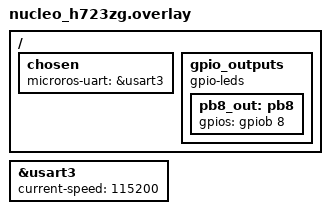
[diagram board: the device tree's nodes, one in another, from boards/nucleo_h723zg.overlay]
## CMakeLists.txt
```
# SPDX-License-Identifier: Apache-2.0
cmake_minimum_required(VERSION 3.14)

find_package(Zephyr REQUIRED HINTS $ENV{ZEPHYR_BASE})
project(wamr_led_toggle)
enable_language(ASM)

set(WAMR_BUILD_PLATFORM "zephyr")
set(WAMR_BUILD_INTERP 1)
set(WAMR_BUILD_LIBC_BUILTIN 1)
set(WAMR_BUILD_LIBC_WASI 0)
set(WAMR_BUILD_FAST_INTERP 0)
set(WAMR_BUILD_GLOBAL_HEAP_POOL 1)
set(WAMR_BUILD_GLOBAL_HEAP_SIZE 131072)

set(WAMR_ROOT_DIR $ENV{WAMR_ROOT} CACHE PATH "Path to WAMR root directory")

include(${WAMR_ROOT_DIR}/build-scripts/runtime_lib.cmake)

target_sources(app PRIVATE
    ${WAMR_RUNTIME_LIB_SOURCE}
    ${CMAKE_CURRENT_SOURCE_DIR}/src/main.c
    ${CMAKE_CURRENT_SOURCE_DIR}/src/wasm_export_native.c
)

target_include_directories(app PRIVATE
    ${APP_INC_DIRS}
    ${CMAKE_CURRENT_SOURCE_DIR}/include
)
```

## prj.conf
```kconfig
# Configurazione Memoria
CONFIG_NEWLIB_LIBC=y
CONFIG_COMMON_LIBC_MALLOC_ARENA_SIZE=0
CONFIG_HEAP_MEM_POOL_SIZE=2048

# Stack per l'interprete WAMR (fondamentale per evitare Hard Fault)
CONFIG_MAIN_STACK_SIZE=8192
CONFIG_SYSTEM_WORKQUEUE_STACK_SIZE=4096

# Periferiche e Log
CONFIG_GPIO=y
CONFIG_LOG=y
CONFIG_LOG_DEFAULT_LEVEL=3
CONFIG_UART_CONSOLE=y
CONFIG_CONSOLE=y

# Supporto Floating Point (Essenziale per FFT)
CONFIG_FPU=y

CONFIG_CACHE_MANAGEMENT=y
```

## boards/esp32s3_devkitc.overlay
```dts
/ {
    aliases {
        led0 = &d13_led;
    };
    leds {
        compatible = "gpio-leds";
        d13_led: d13 {
            gpios = <&gpio0 13 GPIO_ACTIVE_HIGH>;
        };
    };
};
```

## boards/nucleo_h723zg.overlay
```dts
/*
 * nucleo_h723zg.overlay
 *
 * NUCLEO-H723ZG: USART3 è collegato alla ST-Link (Virtual COM Port)
 * su PD8 (TX) / PD9 (RX).
 */
/ {
    chosen {
        microros-uart = &usart3;
    };
    gpio_outputs {
        compatible = "gpio-leds";
        pb8_out: pb8 {
            gpios = <&gpiob 8 GPIO_ACTIVE_HIGH>;
        };
    };
};

&usart3 {
    status = "okay";
    current-speed = <115200>;
};
```

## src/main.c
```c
#include <zephyr/kernel.h>
#include <zephyr/device.h>
#include <zephyr/drivers/gpio.h>
#include <zephyr/logging/log.h>
#include "wasm_export.h"
#include "wasm_native.h"
#include "wamr_benchmark.h"

LOG_MODULE_REGISTER(main, LOG_LEVEL_INF);

/* ── WAMR sizing ─────────────────────────────────────────────────────────── */
#define WASM_STACK_SIZE   8192
#define WASM_HEAP_SIZE    8192




/* ── main ─────────────────────────────────────────────────────────────────── */
int main(void)
{
    printk("WAMR FFT Benchmark - starting");

    SysTick->CTRL = 0; // Disable SysTick
    __disable_irq();    // Optional: disable all IRQs to reduce

    SCB_EnableDCache();
    SCB_EnableICache();

    /* WAMR init */
    RuntimeInitArgs init_args = {0};
    init_args.mem_alloc_type = Alloc_With_System_Allocator;
    if (!wasm_runtime_full_init(&init_args)) {
        printk("WAMR init failed");
        return -ENOMEM;
    }

    /* Registra funzioni native GPIO */
    if (!register_native_functions()) {
        printk("Native registration failed");
        wasm_runtime_destroy();
        return -EFAULT;
    }

    /* Carica modulo WASM */
    char error_buf[128];
    wasm_module_t module = wasm_runtime_load(
        (uint8_t *)wamr_benchmark_aot, wamr_benchmark_aot_len,
        error_buf, sizeof(error_buf));
    if (!module) {
        printk("Load failed: %s", error_buf);
        wasm_runtime_destroy();
        return -EINVAL;
    }

    /* Istanzia */
    wasm_module_inst_t instance = wasm_runtime_instantiate(
        module, WASM_STACK_SIZE, WASM_HEAP_SIZE,
        error_buf, sizeof(error_buf));
    if (!instance) {
        printk("Instantiate failed: %s", error_buf);
        wasm_runtime_unload(module);
        wasm_runtime_destroy();
        return -EINVAL;
    }

    wasm_exec_env_t exec_env =
        wasm_runtime_create_exec_env(instance, WASM_STACK_SIZE);
    if (!exec_env) {
        printk("Failed to create exec_env\\n");
        wasm_runtime_deinstantiate(instance);
        wasm_runtime_unload(module);
        wasm_runtime_destroy();
        return -ENOMEM;
    }

     wasm_function_inst_t func =
        wasm_runtime_lookup_function(instance, "app_main");
    if (!func) {
        printk("app_main not found\\n");
        wasm_runtime_destroy_exec_env(exec_env);
        wasm_runtime_deinstantiate(instance);
        wasm_runtime_unload(module);
        wasm_runtime_destroy();
        return -ENOENT;
    }

    int ret = 0;
    if (!wasm_runtime_call_wasm(exec_env, func, 0, NULL)) {
        const char *exc = wasm_runtime_get_exception(instance);
        printk("Exec error: %s\\n", exc ? exc : "unknown");
        ret = -EFAULT;
    } else {
        printk("WASM benchmark completed\\n");
    }
}
```

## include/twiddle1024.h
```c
#ifndef TWIDDLE1024_H
#define TWIDDLE1024_H

/* Twiddle factors for radix-2 DIT FFT, N=1024 */
/* W[k] = cos(2*pi*k/N) - j*sin(2*pi*k/N) */

#define TWIDDLE_N 1024
#define TWIDDLE_HALF (TWIDDLE_N/2)

/* Cosine values */
static const float twiddle_cos[TWIDDLE_HALF] = {
    1.0000000000f, 0.9999811753f, 0.9999247018f, 0.9998305818f,
    0.9996988187f, 0.9995294175f, 0.9993223846f, 0.9990777278f,
    0.9987954562f, 0.9984755806f, 0.9981181129f, 0.9977230666f,
    0.9972904567f, 0.9968202993f, 0.9963126122f, 0.9957674145f,
    0.9951847267f, 0.9945645707f, 0.9939069700f, 0.9932119492f,
    0.9924795346f, 0.9917097537f, 0.9909026354f, 0.9900582103f,
    0.9891765100f, 0.9882575677f, 0.9873014182f, 0.9863080972f,
    0.9852776424f, 0.9842100924f, 0.9831054874f, 0.9819638691f,
    0.9807852804f, 0.9795697657f, 0.9783173707f, 0.9770281427f,
    0.9757021300f, 0.9743393828f, 0.9729399522f, 0.9715038910f,
    0.9700312532f, 0.9685220943f, 0.9669764710f, 0.9653944417f,
    0.9637760658f, 0.9621214043f, 0.9604305194f, 0.9587034749f,
    0.9569403357f, 0.9551411683f, 0.9533060404f, 0.9514350210f,
    0.9495281806f, 0.9475855910f, 0.9456073254f, 0.9435934582f,
    0.9415440652f, 0.9394592236f, 0.9373390119f, 0.9351835099f,
    0.9329927988f, 0.9307669611f, 0.9285060805f, 0.9262102421f,
    0.9238795325f, 0.9215140393f, 0.9191138517f, 0.9166790599f,
    0.9142097557f, 0.9117060320f, 0.9091679831f, 0.9065957045f,
    0.9039892931f, 0.9013488470f, 0.8986744657f, 0.8959662498f,
    0.8932243012f, 0.8904487232f, 0.8876396204f, 0.8847970984f,
    0.8819212643f, 0.8790122264f, 0.8760700942f, 0.8730949784f,
    0.8700869911f, 0.8670462455f, 0.8639728561f, 0.8608669386f,
    0.8577286100f, 0.8545579884f, 0.8513551931f, 0.8481203448f,
    0.8448535652f, 0.8415549774f, 0.8382247056f, 0.8348628750f,
    0.8314696123f
    /* continua fino a 512 valori */
};

/* Sine values (negativi per FFT forward) */
static const float twiddle_sin[TWIDDLE_HALF] = {
   -0.0000000000f, -0.0061358846f, -0.0122715383f, -0.0184067299f,
   -0.0245412285f, -0.0306748032f, -0.0368072229f, -0.0429382569f,
   -0.0490676743f, -0.0551952443f, -0.0613207363f, -0.0674439196f,
   -0.0735645636f, -0.0796824380f, -0.0857973123f, -0.0919089565f,
   -0.0980171403f, -0.1041216339f, -0.1102222073f, -0.1163186309f,
   -0.1224106752f, -0.1284981108f, -0.1345807085f, -0.1406582393f,
   -0.1467304745f, -0.1527971853f, -0.1588581433f, -0.1649131205f,
   -0.1709618888f, -0.1770042204f, -0.1830398880f, -0.1890686641f,
   -0.1950903220f, -0.2011046348f, -0.2071113762f, -0.2131103199f,
   -0.2191012402f, -0.2250839114f, -0.2310581083f, -0.2370236060f,
   -0.2429801799f, -0.2489276057f, -0.2548656596f, -0.2607941179f,
   -0.2667127575f, -0.2726213554f, -0.2785196894f, -0.2844075372f,
   -0.2902846773f, -0.2961508882f, -0.3020059493f, -0.3078496400f,
   -0.3136817404f, -0.3195020308f, -0.3253102922f, -0.3311063058f,
   -0.3368898534f, -0.3426607173f, -0.3484186802f, -0.3541635254f,
   -0.3598950365f, -0.3656129978f, -0.3713171940f, -0.3770074102f,
   -0.3826834324f, -0.3883450467f, -0.3939920401f, -0.3996241998f,
   -0.4052413140f, -0.4108431711f, -0.4164295601f, -0.4220002708f,
   -0.4275550934f, -0.4330938189f, -0.4386162385f, -0.4441221446f,
   -0.4496113297f, -0.4550835871f, -0.4605387110f, -0.4659764958f,
   -0.4713967368f, -0.4767992301f, -0.4821837721f, -0.4875501601f,
   -0.4928981922f, -0.4982276670f, -0.5035383837f, -0.5088301425f,
   -0.5141027442f, -0.5193559902f, -0.5245896827f, -0.5298036247f,
   -0.5349976199f, -0.5401714727f, -0.5453249884f, -0.5504579729f,
   -0.5555702330f
   /* continua fino a 512 valori */
};

#endif /* TWIDDLE1024_H */
```

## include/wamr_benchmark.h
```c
unsigned char wamr_benchmark_aot[] = {
  0x00, 0x61, 0x6f, 0x74, 0x05, 0x00, 0x00, 0x00, 0x00, 0x00, 0x00, 0x00,
  0x30, 0x00, 0x00, 0x00, 0x00, 0x00, 0x00, 0x00, 0x01, 0x00, 0x28, 0x00,
  0x01, 0x00, 0x00, 0x00, 0x00, 0x00, 0x00, 0x05, 0x00, 0x00, 0x00, 0x00,
  0x00, 0x00, 0x00, 0x00, 0x00, 0x00, 0x00, 0x00, 0x00, 0x00, 0x00, 0x00,
  0x74, 0x68, 0x75, 0x6d, 0x62, 0x76, 0x37, 0x65, 0x6d, 0x00, 0x00, 0x00,
  0x00, 0x00, 0x00, 0x00, 0x01, 0x00, 0x00, 0x00, 0xc0, 0x00, 0x00, 0x00,
  0x00, 0x00, 0x00, 0x00, 0x01, 0x00, 0x00, 0x00, 0x00, 0x00, 0x00, 0x00,
  0x00, 0x00, 0x01, 0x00, 0x01, 0x00, 0x00, 0x00, 0x01, 0x00, 0x00, 0x00,
  0x00, 0x00, 0x00, 0x00, 0x00, 0x00, 0x00, 0x00, 0x01, 0x00, 0x00, 0x00,
  0x70, 0x01, 0x00, 0x00, 0x01, 0x00, 0x00, 0x00, 0x01, 0x00, 0x00, 0x00,
  0x00, 0x00, 0x00, 0x00, 0x01, 0x00, 0x00, 0x00, 0x00, 0x00, 0x00, 0x00,
  0x00, 0x00, 0x00, 0x00, 0x00, 0x00, 0x00, 0x00, 0x01, 0x00, 0x00, 0x00,
  0x7f, 0x01, 0x00, 0x00, 0x41, 0x00, 0x00, 0x00, 0x00, 0x00, 0x01, 0x00,
  0x01, 0x00, 0x00, 0x00, 0x00, 0x00, 0x04, 0x00, 0x65, 0x6e, 0x76, 0x00,
  0x0e, 0x00, 0x72, 0x75, 0x6e, 0x5f, 0x62, 0x65, 0x6e, 0x63, 0x68, 0x6d,
  0x61, 0x72, 0x6b, 0x00, 0x01, 0x00, 0x00, 0x00, 0xff, 0xff, 0xff, 0xff,
  0xff, 0xff, 0xff, 0xff, 0x00, 0x00, 0x00, 0x00, 0x00, 0x00, 0x00, 0x00,
  0xff, 0xff, 0xff, 0xff, 0x00, 0x00, 0x00, 0x00, 0x00, 0x00, 0x00, 0x00,
  0xff, 0xff, 0xff, 0xff, 0x00, 0x00, 0x00, 0x00, 0x00, 0x00, 0x00, 0x00,
  0x00, 0x00, 0x00, 0x00, 0x01, 0x00, 0x00, 0x00, 0x11, 0x00, 0x2e, 0x61,
  0x6f, 0x74, 0x5f, 0x73, 0x74, 0x61, 0x63, 0x6b, 0x5f, 0x73, 0x69, 0x7a,
  0x65, 0x73, 0x00, 0x00, 0x04, 0x00, 0x00, 0x00, 0x30, 0x00, 0x00, 0x00,
  0x02, 0x00, 0x00, 0x00, 0x40, 0x00, 0x00, 0x00, 0x00, 0x00, 0x00, 0x00,
  0x80, 0xb5, 0x82, 0xb0, 0x40, 0xf2, 0x00, 0x01, 0xc0, 0xf2, 0x00, 0x01,
  0x09, 0x68, 0x01, 0xaa, 0x51, 0x1a, 0x07, 0xd3, 0x02, 0x69, 0x91, 0x42,
  0x04, 0xd3, 0x02, 0xb0, 0xbd, 0xe8, 0x80, 0x40, 0x06, 0xe0, 0x00, 0xbf,
  0x80, 0x68, 0x0b, 0x21, 0xff, 0xf7, 0xfe, 0xff, 0x02, 0xb0, 0x80, 0xbd,
  0xc3, 0x68, 0x00, 0x21, 0x00, 0x22, 0xff, 0xf7, 0xfe, 0xbf, 0x00, 0x00,
  0x03, 0x00, 0x00, 0x00, 0x10, 0x00, 0x00, 0x00, 0x00, 0x00, 0x00, 0x00,
  0x00, 0x00, 0x00, 0x00, 0x00, 0x00, 0x00, 0x00, 0x00, 0x00, 0x00, 0x00,
  0x04, 0x00, 0x00, 0x00, 0x25, 0x00, 0x00, 0x00, 0x02, 0x00, 0x00, 0x00,
  0x00, 0x00, 0x00, 0x00, 0x02, 0x00, 0x07, 0x00, 0x6d, 0x65, 0x6d, 0x6f,
  0x72, 0x79, 0x00, 0x00, 0x01, 0x00, 0x00, 0x00, 0x00, 0x00, 0x09, 0x00,
  0x61, 0x70, 0x70, 0x5f, 0x6d, 0x61, 0x69, 0x6e, 0x00, 0x00, 0x00, 0x00,
  0x05, 0x00, 0x00, 0x00, 0xb4, 0x00, 0x00, 0x00, 0x04, 0x00, 0x00, 0x00,
  0x00, 0x00, 0x00, 0x00, 0x0c, 0x00, 0x00, 0x00, 0x20, 0x00, 0x00, 0x00,
  0x3c, 0x00, 0x00, 0x00, 0x50, 0x00, 0x00, 0x00, 0x0a, 0x00, 0x2e, 0x72,
  0x65, 0x6c, 0x2e, 0x74, 0x65, 0x78, 0x74, 0x00, 0x11, 0x00, 0x2e, 0x61,
  0x6f, 0x74, 0x5f, 0x73, 0x74, 0x61, 0x63, 0x6b, 0x5f, 0x73, 0x69, 0x7a,
  0x65, 0x73, 0x00, 0x00, 0x1a, 0x00, 0x61, 0x6f, 0x74, 0x5f, 0x73, 0x65,
  0x74, 0x5f, 0x65, 0x78, 0x63, 0x65, 0x70, 0x74, 0x69, 0x6f, 0x6e, 0x5f,
  0x77, 0x69, 0x74, 0x68, 0x5f, 0x69, 0x64, 0x00, 0x12, 0x00, 0x61, 0x6f,
  0x74, 0x5f, 0x69, 0x6e, 0x76, 0x6f, 0x6b, 0x65, 0x5f, 0x6e, 0x61, 0x74,
  0x69, 0x76, 0x65, 0x00, 0x01, 0x00, 0x00, 0x00, 0x00, 0x00, 0x00, 0x00,
  0x04, 0x00, 0x00, 0x00, 0x04, 0x00, 0x00, 0x00, 0x00, 0x00, 0x00, 0x00,
  0x2f, 0x00, 0x00, 0x00, 0x01, 0x00, 0x00, 0x00, 0x08, 0x00, 0x00, 0x00,
  0x00, 0x00, 0x00, 0x00, 0x30, 0x00, 0x00, 0x00, 0x01, 0x00, 0x00, 0x00,
  0x28, 0x00, 0x00, 0x00, 0x00, 0x00, 0x00, 0x00, 0x0a, 0x00, 0x00, 0x00,
  0x02, 0x00, 0x00, 0x00, 0x36, 0x00, 0x00, 0x00, 0x00, 0x00, 0x00, 0x00,
  0x1e, 0x00, 0x00, 0x00, 0x03, 0x00, 0x00, 0x00
};
unsigned int wamr_benchmark_aot_len = 596;
```

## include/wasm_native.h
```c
/*
 * src/wasm_native_led.h
 *
 * Dichiarazioni per le funzioni native (host-side) esposte al modulo WASM.
 */

#ifndef WASM_NATIVE_LED_H
#define WASM_NATIVE_LED_H

#include <zephyr/drivers/gpio.h>
#include "wasm_export.h"

/* Chiamata da main.c dopo init runtime, prima del load del modulo */
bool register_native_functions(void);


#endif /* WASM_NATIVE_LED_H */
```

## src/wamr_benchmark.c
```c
/*
 * wasm_app/led_toggle.c
 *
 * WASM-side application.
 * Compiled with wasi-sdk (clang --target=wasm32-unknown-unknown) to produce
 * wamr_benchmark.wasm, which is then xxd-converted to led_toggle_wasm.h.
 *
 * Build command (from wasm_app/):
 *
 * /opt/wasi-sdk/bin/clang --target=wasm32-unknown-unknown -nostdlib -Wl,--no-entry -Wl,--export=app_main -Wl,--allow-undefined -O3 -o wamr_benchmark.wasm wamr_benchmark.c
 *
 *   xxd -i wamr_benchmark.wasm > wamr_benchmark.h
 *   # Then rename the array/length symbols to wamr_benchmark_wasm / wamr_benchmark_wasm_len
 *
 */

/* Declare the host-provided functions as imports */
extern void run_benchmark();

/* ------------------------------------------------------------------ */
/*  Entry point called by the WAMR host                               */
/* ------------------------------------------------------------------ */
__attribute__((export_name("app_main")))
void app_main(void)
{
    run_benchmark();
}
```

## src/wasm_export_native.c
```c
/*
 * src/wasm_export_native.c
 *
 * Implements the native functions that the WASM module calls through
 * WAMR's NativeSymbol mechanism.
 *
 * Signature strings follow WAMR conventions:
 *   '(' param-types ')' return-type
 *   i = i32,  I = i64,  f = f32,  F = f64,  * = pointer,  $ = string
 *   Empty params/return → "()" or ""
 */

#include <zephyr/kernel.h>
#include <zephyr/drivers/gpio.h>
#include <zephyr/logging/log.h>
#include <math.h>
#include "wasm_export.h"
#include "wasm_native.h"
#include "twiddle1024.h"

LOG_MODULE_REGISTER(wamr_fft, LOG_LEVEL_INF); 
#define N_MEAS 50
#define T_CRIT_95 2.0096f  // t-student per df=49

#define N_FFT 1024
#define NUM_ITER 100



static float buf[2 * N_FFT];



float misure[50];

// Bit reversal
static void bit_reverse(float *b)
{
    int j = 0;
    for (int i = 0; i < N_FFT; ++i) {
        if (i < j) {
            float tr = b[2*i+0];
            float ti = b[2*i+1];
            b[2*i+0] = b[2*j+0];
            b[2*i+1] = b[2*j+1];
            b[2*j+0] = tr;
            b[2*j+1] = ti;
        }
    int bit = N_FFT >> 1;

    while (j & bit) { j ^= bit; bit >>= 1; }
    j |= bit;
    }
}
 
// Radix-2 FFT
static void fft_radix2(float *b)
{
    bit_reverse(b);
    for (int len = 2; len <= N_FFT; len <<= 1) {
        int half_len = len >> 1;
        int stride = N_FFT / len;
        for (int i = 0; i < N_FFT; i += len) {
            for (int j = 0; j < half_len; j++) {
            int idx1 = i + j;
            int idx2 = idx1 + half_len;
            int k = j * stride;
            float wr = twiddle_cos[k];
            float wi = twiddle_sin[k];
            float xr = b[2*idx2+0];
            float xi = b[2*idx2+1];
            float tr = wr*xr - wi*xi;
            float ti = wr*xi + wi*xr;
            float ur = b[2*idx1+0];
            float ui = b[2*idx1+1];
            b[2*idx1+0] = ur + tr;
            b[2*idx1+1] = ui + ti;
            b[2*idx2+0] = ur - tr;
            b[2*idx2+1] = ui - ti;
            }
        }
    }
}

static void fft_init(void)
{
    for (int i = 0; i < N_FFT; ++i) {
        float x = (float)i;
        buf[2 * i + 0] = x;
        buf[2 * i + 1] = 0.5f * x;
    }
}
// FFT core implementation omitted (same as WASM module version)
void fft_bench(int iterations)
{
    for (int k = 0; k < iterations; ++k) {
        fft_radix2(buf);
    }
}
// DWT cycle counter
static void DWT_Init(void)
{
    // Enable trace
    CoreDebug->DEMCR |= CoreDebug_DEMCR_TRCENA_Msk;
    // Reset cycle counter
    DWT->CYCCNT = 0;
    // Enable cycle counter
    DWT->CTRL |= DWT_CTRL_CYCCNTENA_Msk;
}


uint32_t run_single_benchmark(void)
{
    uint32_t total_cycles = 0;
    uint32_t avg_cycles = 0;
    DWT_Init();
    fft_init();
    uint32_t start = DWT->CYCCNT;
    fft_bench(NUM_ITER);
    uint32_t end = DWT->CYCCNT;
    total_cycles = end - start;
    avg_cycles = total_cycles / NUM_ITER;
    return avg_cycles;
}




void compute_confidence_interval(float *misure) {
    float sum = 0.0f;
    float mean, sem, me;
    float variance = 0.0f;

    // Media
    for (int i = 0; i < N_MEAS; i++) {
        sum += misure[i];
    }
    mean = sum / N_MEAS;

    // Varianza (sample variance)
    for (int i = 0; i < N_MEAS; i++) {
        float diff = misure[i] - mean;
        variance += diff * diff;
    }
    variance /= (N_MEAS - 1);

    // Standard error
    sem = sqrtf(variance / N_MEAS);

    // Margine di errore
    me = T_CRIT_95 * sem;

    float ci_low = mean - me;
    float ci_high = mean + me;

    printk("Mean = %f\n", mean);
    printk("SEM = %f\n", sem);
    printk("CI 95%% = [%f, %f]\n", ci_low, ci_high);
}


void run_benchmark_init(void)
{
   
    float sum = 0.0f, sum_sq = 0.0f;

    for (int i = 0; i < N_MEAS; i++) {
        misure[i] = run_single_benchmark();
        sum += misure[i];
        sum_sq += misure[i] * misure[i];
    }

    float mean = sum / N_MEAS;
    float variance = (sum_sq - N_MEAS * mean * mean) / (N_MEAS - 1);
    
    compute_confidence_interval(misure);
}


/* ------------------------------------------------------------------ */
/*  NativeSymbol table                                                 */
/* ------------------------------------------------------------------ */
static NativeSymbol native_symbols[] = {
    { "run_benchmark",   run_benchmark_init,   "()",  NULL },
};

bool register_native_functions(void)
{
    int n = sizeof(native_symbols) / sizeof(native_symbols[0]);
    if (!wasm_runtime_register_natives("env", native_symbols, n)) {
        return false;
    }
    LOG_INF("Registered %d native symbols", n);
    return true;
}
```
